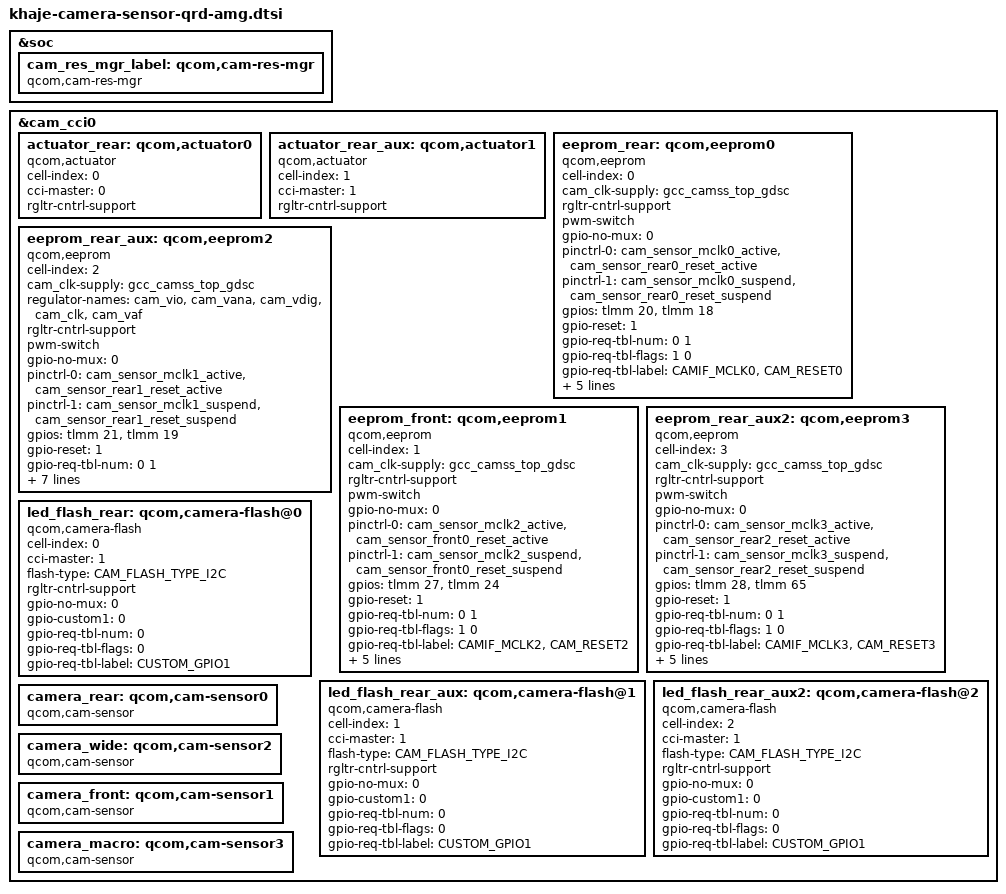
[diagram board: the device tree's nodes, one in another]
#include <dt-bindings/clock/qcom,gcc-khaje.h>
#include <dt-bindings/msm-camera.h>

&soc {
	cam_res_mgr_label: qcom,cam-res-mgr {
		compatible = "qcom,cam-res-mgr";
		status = "ok";
	};
};

&cam_cci0 {
	actuator_rear: qcom,actuator0 {
		cell-index = <0>;
		compatible = "qcom,actuator";
		cci-master = <0>;

		rgltr-cntrl-support;

		status = "ok";
	};

	actuator_rear_aux: qcom,actuator1 {
		cell-index = <1>;
		compatible = "qcom,actuator";
		cci-master = <1>;


		rgltr-cntrl-support;

		status = "ok";
	};

	eeprom_rear: qcom,eeprom0 {
		cell-index = <0>;
		compatible = "qcom,eeprom";

		cam_clk-supply = <&gcc_camss_top_gdsc>;

		rgltr-cntrl-support;
		pwm-switch;

		gpio-no-mux = <0>;
		pinctrl-names = "cam_default", "cam_suspend";
		pinctrl-0 = <&cam_sensor_mclk0_active
				&cam_sensor_rear0_reset_active>;
		pinctrl-1 = <&cam_sensor_mclk0_suspend
				&cam_sensor_rear0_reset_suspend>;
		gpios = <&tlmm 20 0>,
			<&tlmm 18 0>;
		gpio-reset = <1>;
		gpio-req-tbl-num = <0 1>;
		gpio-req-tbl-flags = <1 0>;
		gpio-req-tbl-label = "CAMIF_MCLK0",
					"CAM_RESET0";
		sensor-mode = <0>;
		cci-master = <0>;
		status = "ok";
		clocks = <&gcc GCC_CAMSS_MCLK0_CLK>;
		clock-names = "cam_clk";
		clock-cntl-level = "turbo";
		clock-rates = <19200000>;
	};

	eeprom_rear_aux: qcom,eeprom2 {
		cell-index = <2>;
		compatible = "qcom,eeprom";

		cam_clk-supply = <&gcc_camss_top_gdsc>;
		regulator-names = "cam_vio", "cam_vana", "cam_vdig",
			"cam_clk", "cam_vaf";
		rgltr-cntrl-support;
		pwm-switch;

		gpio-no-mux = <0>;
		pinctrl-names = "cam_default", "cam_suspend";
		pinctrl-0 = <&cam_sensor_mclk1_active
				&cam_sensor_rear1_reset_active>;
		pinctrl-1 = <&cam_sensor_mclk1_suspend
				&cam_sensor_rear1_reset_suspend>;
		gpios = <&tlmm 21 0>,
			<&tlmm 19 0>;
		gpio-reset = <1>;
		gpio-req-tbl-num = <0 1>;
		gpio-req-tbl-flags = <1 0>;
		gpio-req-tbl-label = "CAMIF_MCLK1",
					"CAM_RESET1";
		sensor-mode = <0>;
		cci-master = <1>;
		status = "ok";
		clocks = <&gcc GCC_CAMSS_MCLK1_CLK>;
		clock-names = "cam_clk";
		clock-cntl-level = "turbo";
		clock-rates = <19200000>;
	};

	eeprom_front: qcom,eeprom1 {
		cell-index = <1>;
		compatible = "qcom,eeprom";

		cam_clk-supply = <&gcc_camss_top_gdsc>;

		rgltr-cntrl-support;
		pwm-switch;

		gpio-no-mux = <0>;
		pinctrl-names = "cam_default", "cam_suspend";
		pinctrl-0 = <&cam_sensor_mclk2_active
				&cam_sensor_front0_reset_active>;
		pinctrl-1 = <&cam_sensor_mclk2_suspend
				&cam_sensor_front0_reset_suspend>;
		gpios = <&tlmm 27 0>,
			<&tlmm 24 0>;
		gpio-reset = <1>;
		gpio-req-tbl-num = <0 1>;
		gpio-req-tbl-flags = <1 0>;
		gpio-req-tbl-label = "CAMIF_MCLK2",
					"CAM_RESET2";
		sensor-mode = <0>;
		cci-master = <1>;
		status = "ok";
		clocks = <&gcc GCC_CAMSS_MCLK2_CLK>;
		clock-names = "cam_clk";
		clock-cntl-level = "turbo";
		clock-rates = <24000000>;
	};

	eeprom_rear_aux2: qcom,eeprom3 {
		cell-index = <3>;
		compatible = "qcom,eeprom";

		cam_clk-supply = <&gcc_camss_top_gdsc>;

		rgltr-cntrl-support;
		pwm-switch;

		gpio-no-mux = <0>;
		pinctrl-names = "cam_default", "cam_suspend";
		pinctrl-0 = <&cam_sensor_mclk3_active
				&cam_sensor_rear2_reset_active>;
		pinctrl-1 = <&cam_sensor_mclk3_suspend
				&cam_sensor_rear2_reset_suspend>;
		gpios = <&tlmm 28 0>,
			<&tlmm 65 0>;
		gpio-reset = <1>;
		gpio-req-tbl-num = <0 1>;
		gpio-req-tbl-flags = <1 0>;
		gpio-req-tbl-label = "CAMIF_MCLK3",
					"CAM_RESET3";
		sensor-mode = <0>;
		cci-master = <0>;
		status = "ok";
		clocks = <&gcc GCC_CAMSS_MCLK3_CLK>;
		clock-names = "cam_clk";
		clock-cntl-level = "turbo";
		clock-rates = <19200000>;
	};

	led_flash_rear: qcom,camera-flash@0 {
		cell-index = <0>;
		compatible = "qcom,camera-flash";
		cci-master = <1>;
		flash-type = <CAM_FLASH_TYPE_I2C>;

		rgltr-cntrl-support;

		gpio-no-mux = <0>;
		gpio-custom1 = <0>;
		gpio-req-tbl-num = <0>;
		gpio-req-tbl-flags = <0>;
		gpio-req-tbl-label = "CUSTOM_GPIO1";
		status = "ok";
	};

	led_flash_rear_aux: qcom,camera-flash@1 {
		cell-index = <1>;
		compatible = "qcom,camera-flash";
		cci-master = <1>;
		flash-type = <CAM_FLASH_TYPE_I2C>;

		rgltr-cntrl-support;

		gpio-no-mux = <0>;
		gpio-custom1 = <0>;
		gpio-req-tbl-num = <0>;
		gpio-req-tbl-flags = <0>;
		gpio-req-tbl-label = "CUSTOM_GPIO1";
		status = "ok";
	};

	led_flash_rear_aux2: qcom,camera-flash@2 {
		cell-index = <2>;
		compatible = "qcom,camera-flash";
		cci-master = <1>;
		flash-type = <CAM_FLASH_TYPE_I2C>;


		rgltr-cntrl-support;

		gpio-no-mux = <0>;
		gpio-custom1 = <0>;
		gpio-req-tbl-num = <0>;
		gpio-req-tbl-flags = <0>;
		gpio-req-tbl-label = "CUSTOM_GPIO1";
		status = "ok";
	};

	 /* Rear*/
	camera_rear: qcom,cam-sensor0 {
		compatible = "qcom,cam-sensor";
		status = "ok";
	};

	/*Rear Aux*/
	camera_wide: qcom,cam-sensor2 {
		compatible = "qcom,cam-sensor";
		status = "ok";
	};

	/*Front*/
	camera_front: qcom,cam-sensor1 {
		compatible = "qcom,cam-sensor";
		status = "ok";
	};
	camera_macro: qcom,cam-sensor3 {
		compatible = "qcom,cam-sensor";
		status = "ok";
	};
};
